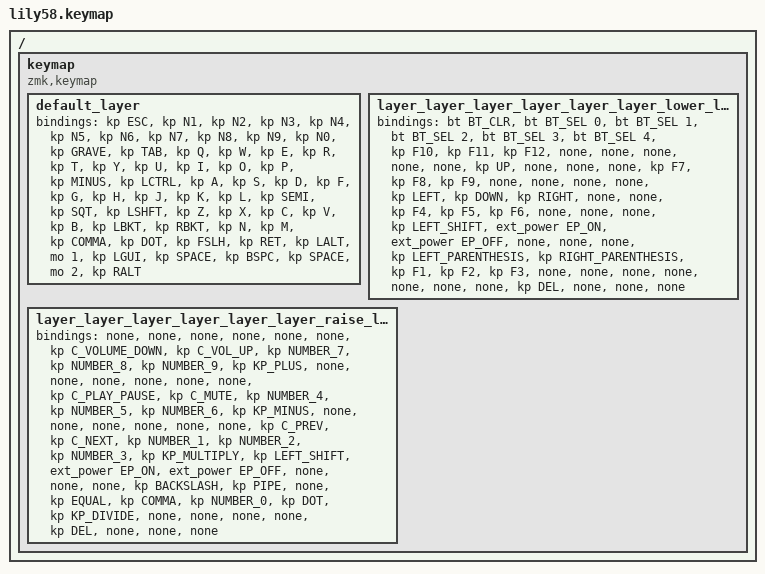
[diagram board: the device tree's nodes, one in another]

/*
 * Copyright (c) 2020 The ZMK Contributors
 *
 * SPDX-License-Identifier: MIT
 */


/* THIS FILE WAS GENERATED!
 *
 * This file was generated automatically. You may or may not want to
 * edit it directly.
 */

#include <behaviors.dtsi>
#include <dt-bindings/zmk/keys.h>
#include <dt-bindings/zmk/bt.h>
#include <dt-bindings/zmk/ext_power.h>

/ {
    keymap {
        compatible = "zmk,keymap";


        default_layer {
            bindings = <
 &kp ESC  &kp N1  &kp N2  &kp N3  &kp N4  &kp N5            &kp N6  &kp N7  &kp N8  &kp N9  &kp N0  &kp GRAVE  &kp TAB   &kp Q   &kp W   &kp E   &kp R   &kp T   &kp Y   &kp U   &kp I   &kp O   &kp P  &kp MINUS  &kp LCTRL   &kp A   &kp S   &kp D   &kp F   &kp G   &kp H   &kp J   &kp K   &kp L  &kp SEMI  &kp SQT  &kp LSHFT   &kp Z   &kp X   &kp C   &kp V   &kp B  &kp LBKT  &kp RBKT   &kp N   &kp M  &kp COMMA  &kp DOT  &kp FSLH  &kp RET  &kp LALT   &mo 1  &kp LGUI  &kp SPACE  &kp BSPC  &kp SPACE   &mo 2  &kp RALT
            >;
        };

        layer_layer_layer_layer_layer_layer_lower_layer {
            bindings = <
 &bt BT_CLR  &bt BT_SEL 0  &bt BT_SEL 1  &bt BT_SEL 2  &bt BT_SEL 3  &bt BT_SEL 4            &kp F10  &kp F11  &kp F12   &none   &none   &none   &none   &none  &kp UP   &none   &none   &none  &kp F7  &kp F8  &kp F9   &none   &none   &none   &none  &kp LEFT  &kp DOWN  &kp RIGHT   &none   &none  &kp F4  &kp F5  &kp F6   &none   &none   &none  &kp LEFT_SHIFT  &ext_power EP_ON  &ext_power EP_OFF   &none   &none   &none  &kp LEFT_PARENTHESIS  &kp RIGHT_PARENTHESIS  &kp F1  &kp F2  &kp F3   &none   &none   &none   &none   &none   &none   &none  &kp DEL   &none   &none   &none
            >;
        };

        layer_layer_layer_layer_layer_layer_raise_layer {
            bindings = <
  &none   &none   &none   &none   &none   &none            &kp C_VOLUME_DOWN  &kp C_VOL_UP  &kp NUMBER_7  &kp NUMBER_8  &kp NUMBER_9  &kp KP_PLUS   &none   &none   &none   &none   &none   &none  &kp C_PLAY_PAUSE  &kp C_MUTE  &kp NUMBER_4  &kp NUMBER_5  &kp NUMBER_6  &kp KP_MINUS   &none   &none   &none   &none   &none   &none  &kp C_PREV  &kp C_NEXT  &kp NUMBER_1  &kp NUMBER_2  &kp NUMBER_3  &kp KP_MULTIPLY  &kp LEFT_SHIFT  &ext_power EP_ON  &ext_power EP_OFF   &none   &none   &none  &kp BACKSLASH  &kp PIPE   &none  &kp EQUAL  &kp COMMA  &kp NUMBER_0  &kp DOT  &kp KP_DIVIDE   &none   &none   &none   &none  &kp DEL   &none   &none   &none
            >;
        };

    };
};
